# MCU_SEC_MMR0_CFG2 register map
Vendor: Texas Instruments
Peripheral module from a debugger description file (folder am65x).
Registers are 32-bit, access per field, reset 0xAA00 unless marked. A register's access mark holds for its fields unless they carry their own. Offsets are as the file gives them; lines under a group give offsets from that group; [hi:lo] are bit positions; {n}, {i} and the like mark numbered series; 'fields as' and 'values as' point back to an identical list; <NAME> marks a mode.

## MCU_SEC_MMR0_CFG2
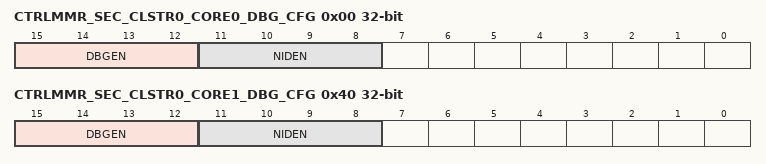
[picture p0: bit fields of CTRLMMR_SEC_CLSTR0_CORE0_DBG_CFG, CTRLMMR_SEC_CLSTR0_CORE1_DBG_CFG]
0x00 CTRLMMR_SEC_CLSTR0_CORE0_DBG_CFG — Configures debug operation for Cluster Core0.
  [15:12] DBGEN rw — Core0 Invasive debug enable.
  [11:8] NIDEN rw — Core0 Non-invasive debug enable.
0x40 CTRLMMR_SEC_CLSTR0_CORE1_DBG_CFG — Configures debug operation for Cluster Core1.
  [15:12] DBGEN rw — Core1 Invasive debug enable.
  [11:8] NIDEN rw — Core1 Non-invasive debug enable.
